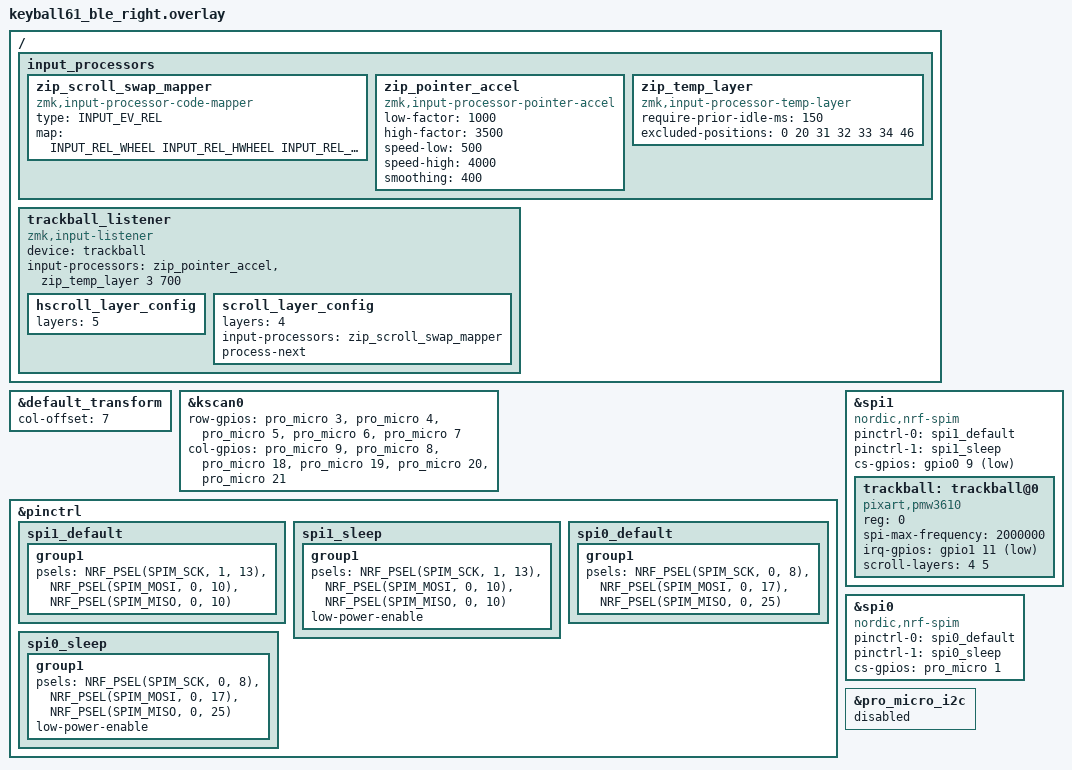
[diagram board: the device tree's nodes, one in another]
/*
 * Copyright (c) 2020 ZMK Contributors
 *
 * SPDX-License-Identifier: MIT
 */
 
#include "keyball61_ble.dtsi"

&default_transform {
    col-offset = <7>;
};

&kscan0 {
    row-gpios
        = <&pro_micro 3 (GPIO_ACTIVE_HIGH | GPIO_PULL_DOWN)>
        , <&pro_micro 4 (GPIO_ACTIVE_HIGH | GPIO_PULL_DOWN)>
        , <&pro_micro 5 (GPIO_ACTIVE_HIGH | GPIO_PULL_DOWN)>
        , <&pro_micro 6 (GPIO_ACTIVE_HIGH | GPIO_PULL_DOWN)>
        , <&pro_micro 7 (GPIO_ACTIVE_HIGH | GPIO_PULL_DOWN)>
        ;
    
	col-gpios
        = <&pro_micro 9  GPIO_ACTIVE_HIGH>
        , <&pro_micro 8  GPIO_ACTIVE_HIGH>
        , <&pro_micro 18 GPIO_ACTIVE_HIGH>
	    , <&pro_micro 19 GPIO_ACTIVE_HIGH>
		, <&pro_micro 20 GPIO_ACTIVE_HIGH>
		, <&pro_micro 21 GPIO_ACTIVE_HIGH>
		;
};

&pinctrl {
    spi1_default: spi1_default {
        group1 {
            psels = <NRF_PSEL(SPIM_SCK, 1, 13)>,
                <NRF_PSEL(SPIM_MOSI, 0, 10)>,
                <NRF_PSEL(SPIM_MISO, 0, 10)>;
        };
    };

    spi1_sleep: spi1_sleep {
        group1 {
            psels = <NRF_PSEL(SPIM_SCK, 1, 13)>,
                <NRF_PSEL(SPIM_MOSI, 0, 10)>,
                <NRF_PSEL(SPIM_MISO, 0, 10)>;
            low-power-enable;
        };
    };
};

&spi1 {
    status = "okay";
    compatible = "nordic,nrf-spim";
    pinctrl-0 = <&spi1_default>;
    pinctrl-1 = <&spi1_sleep>;
    pinctrl-names = "default", "sleep";
    cs-gpios = <&gpio0 9 GPIO_ACTIVE_LOW>;

    trackball: trackball@0 {
        status = "okay";
        compatible = "pixart,pmw3610";
        reg = <0>;
        spi-max-frequency = <2000000>;
        irq-gpios = <&gpio1 11 (GPIO_ACTIVE_LOW | GPIO_PULL_UP)>;
	scroll-layers = <4 5>;
    };
};

/*
 * nice!view on SPI0: MOSI pm2 (P0.17), SCK pm0 (P0.08), CS pm1 (P0.06).
 * pm3 (P0.20, the nice_view_adapter SCK) is ROW0 on this half, so the SPI
 * bus is defined here instead of using nice_view_adapter. The display has
 * no MISO; P0.25 is unused.
 */
&pinctrl {
    spi0_default: spi0_default {
        group1 {
            psels = <NRF_PSEL(SPIM_SCK, 0, 8)>,
                <NRF_PSEL(SPIM_MOSI, 0, 17)>,
                <NRF_PSEL(SPIM_MISO, 0, 25)>;
        };
    };

    spi0_sleep: spi0_sleep {
        group1 {
            psels = <NRF_PSEL(SPIM_SCK, 0, 8)>,
                <NRF_PSEL(SPIM_MOSI, 0, 17)>,
                <NRF_PSEL(SPIM_MISO, 0, 25)>;
            low-power-enable;
        };
    };
};

nice_view_spi: &spi0 {
    compatible = "nordic,nrf-spim";
    pinctrl-0 = <&spi0_default>;
    pinctrl-1 = <&spi0_sleep>;
    pinctrl-names = "default", "sleep";
    cs-gpios = <&pro_micro 1 GPIO_ACTIVE_HIGH>;
};

/* SPI0 and I2C0 share one peripheral on the nRF52840. */
&pro_micro_i2c {
    status = "disabled";
};

#include <zephyr/dt-bindings/input/input-event-codes.h>

/ {
  input_processors {
    zip_scroll_swap_mapper: zip_scroll_swap_mapper {
      compatible = "zmk,input-processor-code-mapper";
      #input-processor-cells = <0>;
      type = <INPUT_EV_REL>;
      map = <INPUT_REL_WHEEL INPUT_REL_HWHEEL
             INPUT_REL_HWHEEL INPUT_REL_WHEEL>;
    };

    // Pointer acceleration in the firmware (modules/pointer-accel), with
    // macOS acceleration turned off (System Settings > Mouse > Advanced >
    // Pointer acceleration), so USB and BLE feel the same with one setting.
    // Until 2026-11-17 macOS accelerated and a transport scaler set the speed
    // per output, because macOS boosts each report by its size and BLE packs
    // several sensor readings into one: BLE 400, 480, 500 at 15 ms, 600 and
    // 700 at 7.5 ms (700 felt right), USB 720. The scaler module is kept.
    //
    // Sensor at ~31.5 counts per mm of ball surface (800 CPI nominal; 700 on
    // keyball61_nv with the roBa cup, which reads 14% high). Gain is
    // low-factor up to speed-low, high-factor from speed-high, a smooth ramp
    // between. Keep the ramp below ordinary flick speed (see the values).
    // Tried with the old wide curve (500-5000 counts/s): low 0.8x (short moves
    // ever so slightly fast), high 2.5x (flicks too weak), high 3.5x (long
    // flicks too aggressive). Linear 2.0x a touch slow, linear 2.3x too
    // sensitive for small moves (2026-11-20).
    zip_pointer_accel: zip_pointer_accel {
      compatible = "zmk,input-processor-pointer-accel";
      #input-processor-cells = <0>;
      // 2026-11-21: real acceleration again, 1.0x for fine aiming up to
      // 500 counts/s, ramping to 3.5x from 2500 (10 counts per 4 ms reading).
      // Gray ball, 2026-11-21: 3.0x, then 3.5x with the ramp to 5000 felt the
      // same. Ordinary flicks are 5-20 counts per reading (1250-5000/s), so
      // they sat low on that ramp and the top gain barely applied.
      // Everything tuned 2026-11-17 to 11-20 was on a dark purple ball the
      // sensor's infrared barely sees, so slow movement was lost. That is
      // likely what made back-and-forth flicks walk on the old 0.7x-3.0x
      // curve (the slow return lost counts), and why fine moves needed 1.4x.
      // Some walk is normal for any acceleration, macOS's included.
      // Tried on the purple ball: 0.7x-3.0x (walked), linear 2.0x (a touch
      // slow), linear 2.3x (small moves too sensitive), 1.4x-2.3x over
      // 400-1500 (felt static).
      // 2026-11-24: speed-high 2500 -> 4000. Two tools/aimtest runs at 2500:
      // short (240 px) and mid (720 px) moves overshot (mid 9% and 22% past
      // the target, 4 of 7 by more than 10%), long moves only 3-6%. Quick
      // short flicks reached the top gain too soon.
      low-factor = <1000>;
      high-factor = <3500>;
      speed-low = <500>;
      speed-high = <4000>;
      smoothing = <400>;
    };

    zip_temp_layer: zip_temp_layer {
      compatible = "zmk,input-processor-temp-layer";
      #input-processor-cells = <2>;
      require-prior-idle-ms = <150>;
      // 0 too: the MOUSE layer's &to DEFAULT there must resolve before this processor drops the layer.
      excluded-positions = <0 20 31 32 33 34 46>;
    };
  };

  trackball_listener {
    compatible = "zmk,input-listener";
    device = <&trackball>;
    input-processors = <&zip_pointer_accel>, <&zip_temp_layer 3 700>;

    hscroll_layer_config {
      layers = <5>;
    };

    scroll_layer_config {
      layers = <4>;
      input-processors = <&zip_scroll_swap_mapper>;
      process-next;
    };
  };
};
